# APM32L07x register map
File version: 1.0
CPU: CM0+ r0p0, little endian, MPU, no FPU, 4 interrupt priority bits
Registers are 32-bit, read-write, reset 0x0 unless marked. A register's access mark holds for its fields unless they carry their own. Offsets are from the block's base; [hi:lo] are bit positions; {n}, {i} and the like mark numbered series; 'fields as' and 'values as' point back to an identical list.

## RTC — Real-time clock
Base 0x40002800
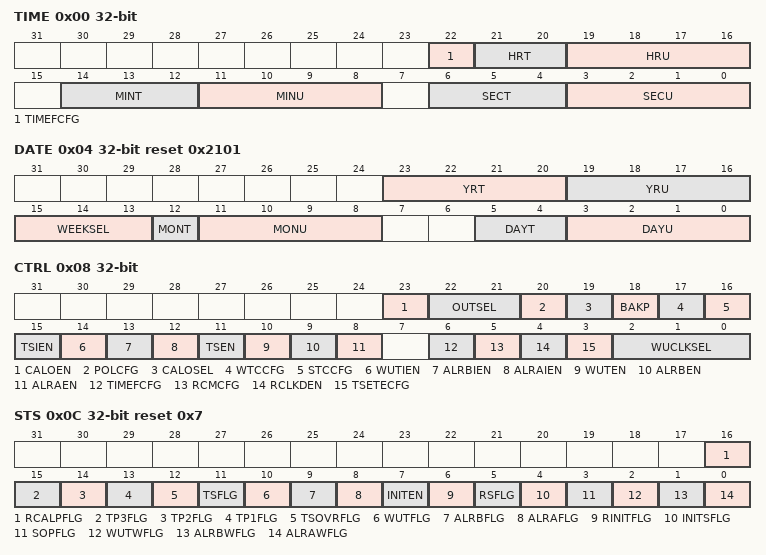
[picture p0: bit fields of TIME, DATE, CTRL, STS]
0x00 TIME
  [22] TIMEFCFG — AM/PM notation
  [21:20] HRT — Hour tens in BCD format
  [19:16] HRU — Hour units in BCD format
  [14:12] MINT — Minute tens in BCD format
  [11:8] MINU — Minute units in BCD format
  [6:4] SECT — Second tens in BCD format
  [3:0] SECU — Second units in BCD format
0x04 DATE reset 0x2101
  [23:20] YRT — Year tens in BCD format
  [19:16] YRU — Year units in BCD format
  [15:13] WEEKSEL — Week day units
  [12] MONT — Month tens in BCD format
  [11:8] MONU — Month units in BCD format
  [5:4] DAYT — Date tens in BCD format
  [3:0] DAYU — Date units in BCD format
0x08 CTRL access per field — control register
  [23] CALOEN rw — Calibration output enable
  [22:21] OUTSEL rw — Output selection
  [20] POLCFG rw — Output polarity
  [19] CALOSEL rw — Calibration output selection
  [18] BAKP rw — Backup
  [17] WTCCFG wo — Lessen 1 hour (winter time change)
  [16] STCCFG wo — Add 1 hour (summer time change)
  [15] TSIEN rw — Time-stamp interrupt enable
  [14] WUTIEN rw — Wakeup timer interrupt enable
  [13] ALRBIEN rw — Alarm B interrupt enable
  [12] ALRAIEN rw — Alarm A interrupt enable
  [11] TSEN rw — timestamp enable
  [10] WUTEN rw — Wakeup timer enable
  [9] ALRBEN rw — Alarm B enable
  [8] ALRAEN rw — Alarm A enable
  [6] TIMEFCFG rw — Hour format
  [5] RCMCFG rw — Bypass the shadow registers
  [4] RCLKDEN rw — RTC_REFIN reference clock detection enable (50 or 60 Hz)
  [3] TSETECFG rw — Time-stamp event active edge
  [2:0] WUCLKSEL rw — Wakeup clock selection
0x0C STS access per field reset 0x7 — initialization and status register
  [16] RCALPFLG ro — Recalibration pending Flag
  [15] TP3FLG rw — RTC_TAMP3 detection flag
  [14] TP2FLG rw — RTC_TAMP2 detection flag
  [13] TP1FLG rw — RTC_TAMP1 detection flag
  [12] TSOVRFLG rw — Time-stamp overflow flag
  [11] TSFLG rw — Time-stamp flag
  [10] WUTFLG rw — Wakeup timer flag
  [9] ALRBFLG rw — Alarm B flag
  [8] ALRAFLG rw — Alarm A flag
  [7] INITEN rw — Initialization mode
  [6] RINITFLG ro — Initialization flag
  [5] RSFLG rw — Registers synchronization flag
  [4] INITSFLG ro — Initialization status flag
  [3] SOPFLG ro — Shift operation pending
  [2] WUTWFLG ro — Wakeup timer write flag
  [1] ALRBWFLG ro — Alarm B write flag
  [0] ALRAWFLG ro — Alarm A write flag
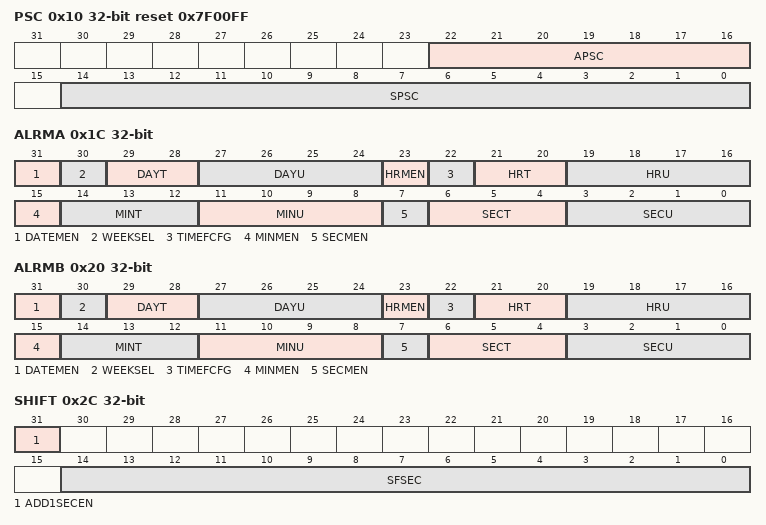
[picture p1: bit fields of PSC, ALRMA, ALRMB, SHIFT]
0x10 PSC reset 0x7F00FF — prescaler register
  [22:16] APSC — Asynchronous prescaler factor
  [14:0] SPSC — Synchronous prescaler factor
0x14 AUTORLD reset 0xFFFF — write protection register
  [14:0] WUAUTORE — Wakeup auto-reload value bits
0x1C ALRMA — alarm A register
  [31] DATEMEN — Alarm A date mask
  [30] WEEKSEL — Week day selection
  [29:28] DAYT — Date tens in BCD format.
  [27:24] DAYU — Date units or day in BCD format.
  [23] HRMEN — Alarm A hours mask
  [22] TIMEFCFG — AM/PM notation
  [21:20] HRT — Hour tens in BCD format.
  [19:16] HRU — Hour units in BCD format.
  [15] MINMEN — Alarm A minutes mask
  [14:12] MINT — Minute tens in BCD format.
  [11:8] MINU — Minute units in BCD format.
  [7] SECMEN — Alarm A seconds mask
  [6:4] SECT — Second tens in BCD format.
  [3:0] SECU — Second units in BCD format.
0x20 ALRMB — alarm B register
  fields as ALRMA
0x24 WRPROT wo — write protection register
  [7:0] KEY — Write protection key
0x28 SUBSEC ro — sub second register
  [15:0] SUBSEC — Sub second value
0x2C SHIFT wo — shift control register
  [31] ADD1SECEN — Reserved
  [14:0] SFSEC — Subtract a fraction of a second
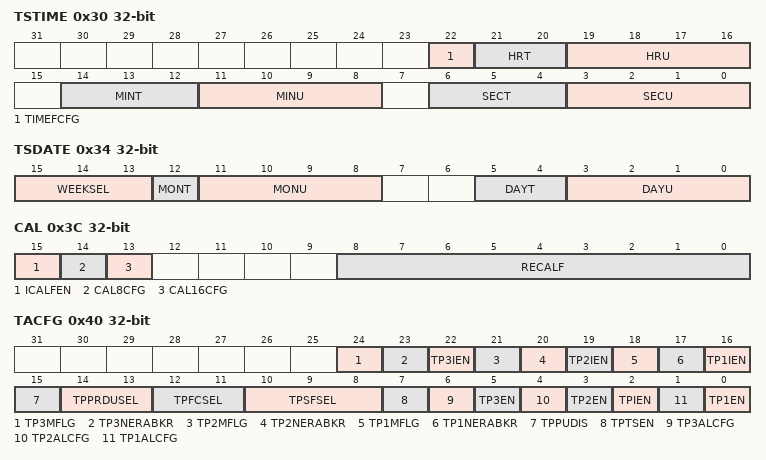
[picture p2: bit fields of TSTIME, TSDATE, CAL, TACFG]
0x30 TSTIME ro — timestamp time register
  [22] TIMEFCFG — AM/PM notation
  [21:20] HRT — Hour tens in BCD format.
  [19:16] HRU — Hour units in BCD format.
  [14:12] MINT — Minute tens in BCD format.
  [11:8] MINU — Minute units in BCD format.
  [6:4] SECT — Second tens in BCD format.
  [3:0] SECU — Second units in BCD format.
0x34 TSDATE ro — timestamp date register
  [15:13] WEEKSEL — Week day units
  [12] MONT — Month tens in BCD format
  [11:8] MONU — Month units in BCD format
  [5:4] DAYT — Date tens in BCD format
  [3:0] DAYU — Date units in BCD format
0x38 TSSUBSEC ro — time-stamp sub second register
  [15:0] SUBSEC — Sub second value
0x3C CAL — calibration register
  [15] ICALFEN — Use an 8-second calibration cycle period
  [14] CAL8CFG — Use a 16-second calibration cycle period
  [13] CAL16CFG — Reserved
  [8:0] RECALF — Calibration minus
0x40 TACFG — tamper and alternate function configuration register
  [24] TP3MFLG — Tamper 3 Mask Flag
  [23] TP3NERABKR — Tamper 3 No Erase the Backup Register Enable
  [22] TP3IEN — Tamper 3 Interrupt Enable
  [21] TP2MFLG — Tamper 2 Mask Flag
  [20] TP2NERABKR — Tamper 2 No Erase the Backup Register Enable
  [19] TP2IEN — Tamper 2 Interrupt Enable
  [18] TP1MFLG — Tamper 1 Mask Flag
  [17] TP1NERABKR — Tamper 1 No Erase the Backup Register Enable
  [16] TP1IEN — Tamper 1 Interrupt Enable
  [15] TPPUDIS — RTC_TAMPx pull-up disable
  [14:13] TPPRDUSEL — RTC_TAMPx precharge duration
  [12:11] TPFCSEL — RTC_TAMPx filter count
  [10:8] TPSFSEL — Tamper sampling frequency
  [7] TPTSEN — Activate timestamp on tamper detection event
  [6] TP3ALCFG — Active level for RTC_TAMP3 input
  [5] TP3EN — RTC_TAMP3 input detection enable
  [4] TP2ALCFG — Active level for RTC_TAMP2 input
  [3] TP2EN — RTC_TAMP2 input detection enable
  [2] TPIEN — Tamper interrupt enable
  [1] TP1ALCFG — Active level for RTC_TAMP1 input
  [0] TP1EN — RTC_TAMP1 input detection enable
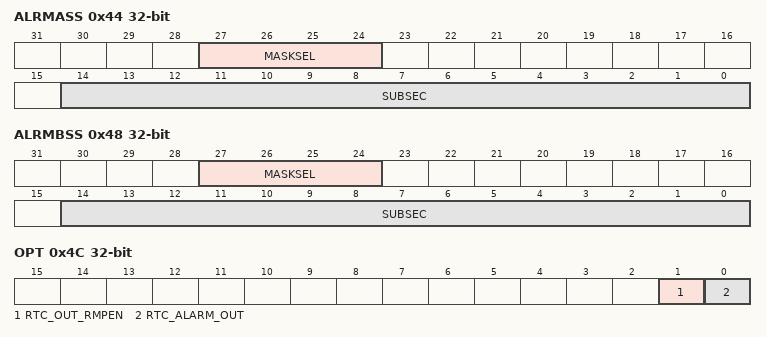
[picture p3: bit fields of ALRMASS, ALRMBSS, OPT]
0x44 ALRMASS — alarm A sub second register
  [27:24] MASKSEL — Mask the most-significant bits starting at this bit
  [14:0] SUBSEC — Sub seconds value
0x48 ALRMBSS — alarm B sub second register
  fields as ALRMASS
0x4C OPT — option register
  [1] RTC_OUT_RMPEN — RTC_OUT Remap Enable
  [0] RTC_ALARM_OUT — RTC_ALARM Output Type on PC13
{0x50+4i} BAKP{i} (i=0..4) — backup register
  [31:0] BAKP — Backup Value Setup
